# PIC32CM1216MC00048 register map
Vendor: Microchip Technology; Series: PIC32CMMC00; File version: 0
CPU: CM0+ r0p0, little endian, MPU, no FPU, VTOR, 2 interrupt priority bits, 27 interrupts
Registers are 32-bit, read-write, reset 0x0 unless marked. A register's access mark holds for its fields unless they carry their own. Offsets are from the block's base; [hi:lo] are bit positions; {n}, {i} and the like mark numbered series; 'fields as' and 'values as' point back to an identical list.

## EIC — External Interrupt Controller
Base 0x40002800
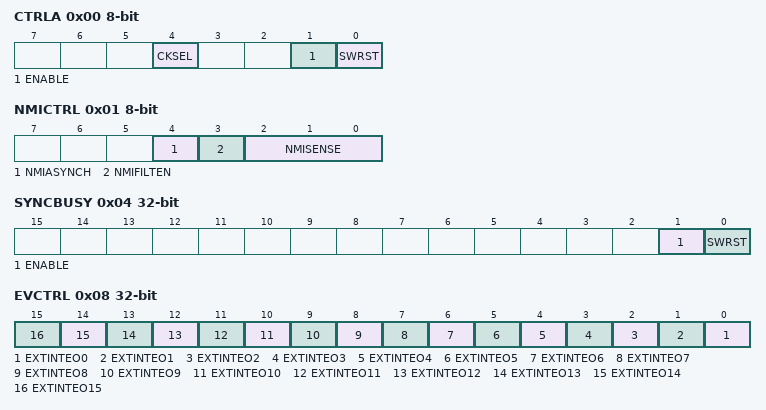
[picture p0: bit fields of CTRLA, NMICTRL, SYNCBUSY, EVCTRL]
0x00 CTRLA 8-bit — Control A
  [4] CKSEL — Clock Selection
    0=CLK_GCLK (Clocked by GCLK); 1=CLK_ULP32K (Clocked by ULP32K)
  [1] ENABLE
  [0] SWRST — Software Reset
0x01 NMICTRL 8-bit — Non-Maskable Interrupt Control
  [4] NMIASYNCH — Asynchronous Edge Detection Mode
    0=SYNC (Edge detection is clock synchronously operated); 1=ASYNC (Edge detection is clock asynchronously operated)
  [3] NMIFILTEN — Non-Maskable Interrupt Filter Enable
  [2:0] NMISENSE — Non-Maskable Interrupt Sense Configuration
    0=NONE (No detection); 1=RISE (Rising-edge detection); 2=FALL (Falling-edge detection); 3=BOTH (Both-edges detection); 4=HIGH (High-level detection); 5=LOW (Low-level detection)
0x02 NMIFLAG 16-bit write-1-clears — Non-Maskable Interrupt Flag Status and Clear
  [0] NMI — Non-Maskable Interrupt
0x04 SYNCBUSY ro — Synchronization Busy
  [1] ENABLE — Enable Synchronization Busy Status
  [0] SWRST — Software Reset Synchronization Busy Status
0x08 EVCTRL — Event Control
  [n] EXTINTEO{n} (n=0..15) — External Interrupt {n} Event Output Enable
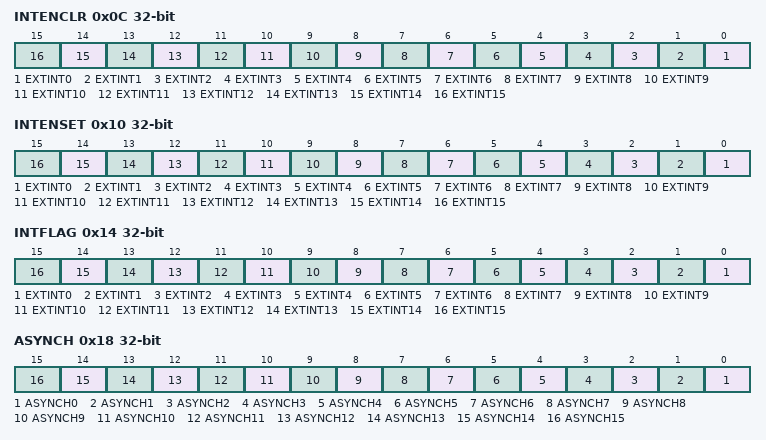
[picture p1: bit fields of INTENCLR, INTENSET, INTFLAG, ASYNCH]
0x0C INTENCLR write-1-clears — Interrupt Enable Clear
  [n] EXTINT{n} (n=0..15) — External Interrupt {n} Enable
0x10 INTENSET write-1-sets — Interrupt Enable Set
  [n] EXTINT{n} (n=0..15) — External Interrupt {n} Enable
0x14 INTFLAG write-1-clears — Interrupt Flag Status and Clear
  [n] EXTINT{n} (n=0..15) — External Interrupt {n}
0x18 ASYNCH — External Interrupt Asynchronous Mode
  [all] fields
    values as NMICTRL.NMIASYNCH
  [n] ASYNCH{n} (n=0..15) — Asynchronous Edge Detection Mode of EXTINT{n}
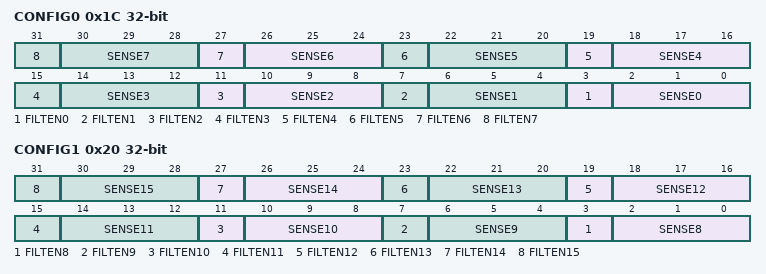
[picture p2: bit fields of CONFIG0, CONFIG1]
0x1C CONFIG0 — External Interrupt Sense Configuration
  [4n+3] FILTEN{n} (n=0..7) — Filter Enable {n}
  [4n+2:4n] SENSE{n} (n=0..7) — Input Sense Configuration {n}
    0=NONE (No detection); 1=RISE (Rising edge detection); 2=FALL (Falling edge detection); 3=BOTH (Both edges detection); 4=HIGH (High level detection); 5=LOW (Low level detection)
0x20 CONFIG1 — External Interrupt Sense Configuration
  [4n-29] FILTEN{n} (n=8..15) — Filter Enable {n}
  [4n-30:4n-32] SENSE{n} (n=8..15) — Input Sense Configuration {n}
    values as CONFIG0.SENSE0

## EVSYS — Event System Interface
Base 0x42000000
0x00 CTRLA 8-bit — Control
  [0] SWRST — Software Reset
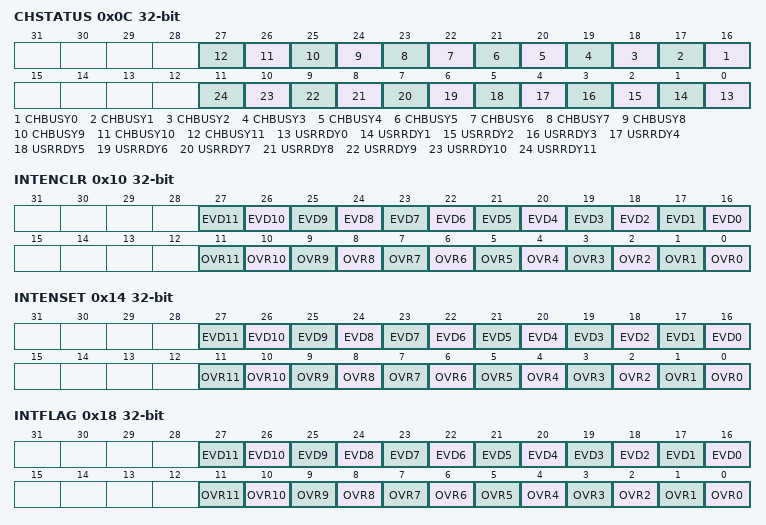
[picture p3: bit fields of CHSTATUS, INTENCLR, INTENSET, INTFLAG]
0x0C CHSTATUS ro — Channel Status
  [n+16] CHBUSY{n} (n=0..11) — Channel {n} Busy
  [n] USRRDY{n} (n=0..11) — Channel {n} User Ready
0x10 INTENCLR write-1-clears — Interrupt Enable Clear
  [n+16] EVD{n} (n=0..11) — Channel {n} Event Detection Interrupt Enable
  [n] OVR{n} (n=0..11) — Channel {n} Overrun Interrupt Enable
0x14 INTENSET write-1-sets — Interrupt Enable Set
  fields as INTENCLR
0x18 INTFLAG write-1-clears — Interrupt Flag Status and Clear
  [n+16] EVD{n} (n=0..11) — Channel {n} Event Detection
  [n] OVR{n} (n=0..11) — Channel {n} Overrun
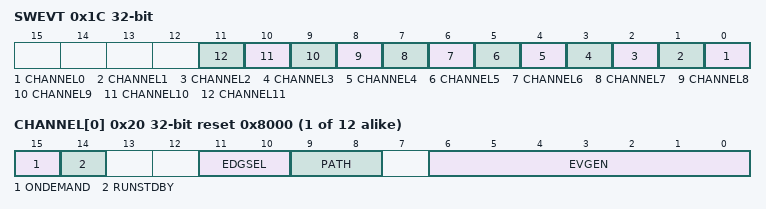
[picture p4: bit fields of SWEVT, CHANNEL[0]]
0x1C SWEVT wo — Software Event
  [n] CHANNEL{n} (n=0..11) — Channel {n} Software Selection
{0x20+4i} CHANNEL[{i}] (i=0..11) reset 0x8000 — Channel n
  [15] ONDEMAND — Generic Clock On Demand
  [14] RUNSTDBY — Run in standby
  [11:10] EDGSEL — Edge Detection Selection
    0=NO_EVT_OUTPUT (No event output when using the resynchronized or synchronous path); 1=RISING_EDGE (Event detection only on the rising edge of the signal from the event generator when using the resynchronized or synchronous path); 2=FALLING_EDGE (Event detection only on the falling edge of the signal from the event generator when using the resynchronized or synchronous path); 3=BOTH_EDGES (Event detection on rising and falling edges of the signal from the event generator when using the resynchronized or synchronous path)
  [9:8] PATH — Path Selection
    0=SYNCHRONOUS (Synchronous path); 1=RESYNCHRONIZED (Resynchronized path); 2=ASYNCHRONOUS (Asynchronous path)
  [6:0] EVGEN — Event Generator Selection
{0x80+4i} USER[{i}] (i=0..46) — User Multiplexer n
  [4:0] CHANNEL — Channel Event Selection
